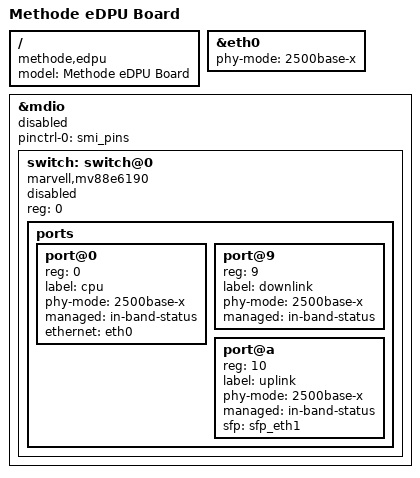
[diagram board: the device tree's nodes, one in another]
// SPDX-License-Identifier: (GPL-2.0+ OR MIT)

/dts-v1/;

#include "armada-3720-uDPU.dtsi"

/ {
	model = "Methode eDPU Board";
	compatible = "methode,edpu", "marvell,armada3720", "marvell,armada3710";
};

&eth0 {
	phy-mode = "2500base-x";
};

/*
 * External MV88E6361 switch is only available on v2 of the board.
 * U-Boot will enable the MDIO bus and switch nodes.
 */
&mdio {
	status = "disabled";
	pinctrl-names = "default";
	pinctrl-0 = <&smi_pins>;

	/* Actual device is MV88E6361 */
	switch: switch@0 {
		compatible = "marvell,mv88e6190";
		#address-cells = <1>;
		#size-cells = <0>;
		reg = <0>;
		status = "disabled";

		ports {
			#address-cells = <1>;
			#size-cells = <0>;

			port@0 {
				reg = <0>;
				label = "cpu";
				phy-mode = "2500base-x";
				managed = "in-band-status";
				ethernet = <&eth0>;
			};

			port@9 {
				reg = <9>;
				label = "downlink";
				phy-mode = "2500base-x";
				managed = "in-band-status";
			};

			port@a {
				reg = <10>;
				label = "uplink";
				phy-mode = "2500base-x";
				managed = "in-band-status";
				sfp = <&sfp_eth1>;
			};
		};
	};
};
